# STM32G081xx register map
File version: 1.0
Registers are 32-bit, read-write, reset 0x0 unless marked. A register's access mark holds for its fields unless they carry their own. Offsets are from the block's base; [hi:lo] are bit positions; {n}, {i} and the like mark numbered series.

## PWR — Power Control
Base 0x40007000
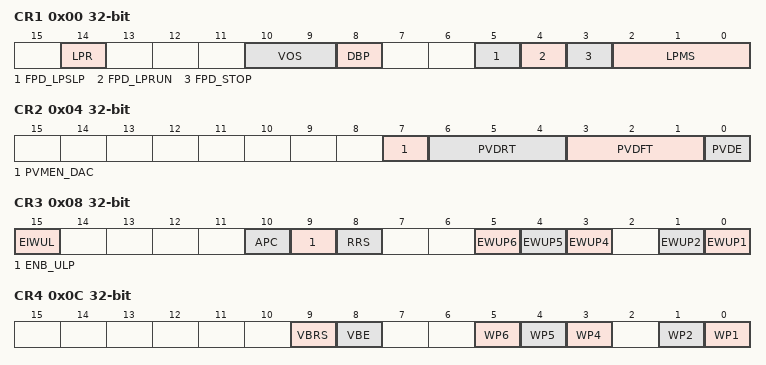
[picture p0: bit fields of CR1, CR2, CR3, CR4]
0x00 CR1 — PWR Power Control Register 1
  [14] LPR — Regulator Low-Power Run mode
  [10:9] VOS — Voltage scaling
    1=SCALE1; 2=SCALE2
  [8] DBP — Disable Backup Domain write protection
  [5] FPD_LPSLP — Flash power down mode during sleep
  [4] FPD_LPRUN — Flash power down mode during run
  [3] FPD_STOP — Flash power down mode during stop
  [2:0] LPMS — Low Power Mode Selection
    0=STOP0; 1=STOP1; 3=STANDBY; 4=SHUTDOWN
0x04 CR2 — PWR Power Control Register 2
  [7] PVMEN_DAC — DAC supply voltage monitoring enable
  [6:4] PVDRT — PVD Rising Threshold Selection bit field
    {v}=PVDHLEVEL_{v} (v=0..7)
  [3:1] PVDFT — PVD Falling Threshold Selection bit field
    {v}=PVDLLEVEL_{v} (v=0..6)
  [0] PVDE — Programmable Voltage Detector Enable
0x08 CR3 — PWR Power Control Register 3
  [15] EIWUL — Enable Internal Wake-up line
  [10] APC — Apply pull-up and pull-down configuration
  [9] ENB_ULP — Enable sampling resistor bridge in the LPMU_RESET block
  [8] RRS — RAM retention in Standby mode
  [5] EWUP6 — Enable WKUP pin 6
  [4] EWUP5 — Enable WKUP pin 5
  [3] EWUP4 — Enable WKUP pin 4
  [1] EWUP2 — Enable WKUP pin 2
  [0] EWUP1 — Enable WKUP pin 1
0x0C CR4 — PWR Power Control Register 4
  [9] VBRS — VBAT Battery charging Resistor Selection
    0=RESISTOR_5K; 1=RESISTOR_1_5K
  [8] VBE — VBAT Battery charging Enable
  [5] WP6 — Wake-Up Pin 6 polarity
  [4] WP5 — Wake-Up Pin 5 polarity
  [3] WP4 — Wake-Up Pin 4 polarity
  [1] WP2 — Wake-Up Pin 2 polarity
  [0] WP1 — Wake-Up Pin 1 polarity
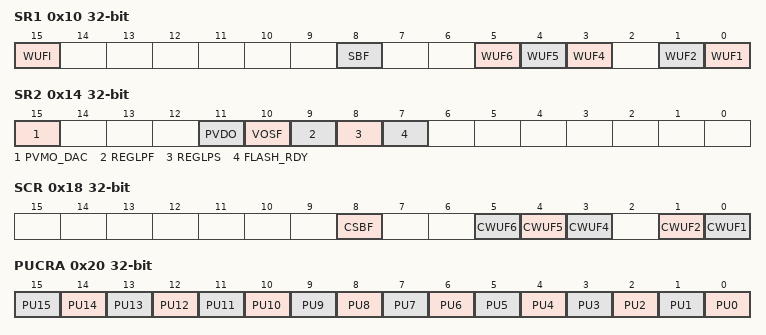
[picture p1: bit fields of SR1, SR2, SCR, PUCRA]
0x10 SR1 — PWR Power Status Register 1
  [15] WUFI — Wakeup Flag Internal
  [8] SBF — Standby Flag
  [5] WUF6 — Wakeup Flag 6
  [4] WUF5 — Wakeup Flag 5
  [3] WUF4 — Wakeup Flag 4
  [1] WUF2 — Wakeup Flag 2
  [0] WUF1 — Wakeup Flag 1
0x14 SR2 — PWR Power Status Register 2
  [15] PVMO_DAC — VDDA monitoring output flag
  [11] PVDO — Power voltage detector output
  [10] VOSF — Voltage Scaling Flag
  [9] REGLPF — Regulator Low Power flag
  [8] REGLPS — Regulator Low Power started
  [7] FLASH_RDY — Flash Ready
0x18 SCR — PWR Power Status Clear Register
  [8] CSBF — Clear Standby Flag
  [5] CWUF6 — Clear Wake-up Flag 6
  [4] CWUF5 — Clear Wake-up Flag 5
  [3] CWUF4 — Clear Wake-up Flag 4
  [1] CWUF2 — Clear Wake-up Flag 2
  [0] CWUF1 — Clear Wake-up Flag 1
0x20 PUCRA — PWR Pull-Up Control Register of port A
  [n] PU{n} (n=0..15) — Pin PA{n} Pull-Up set
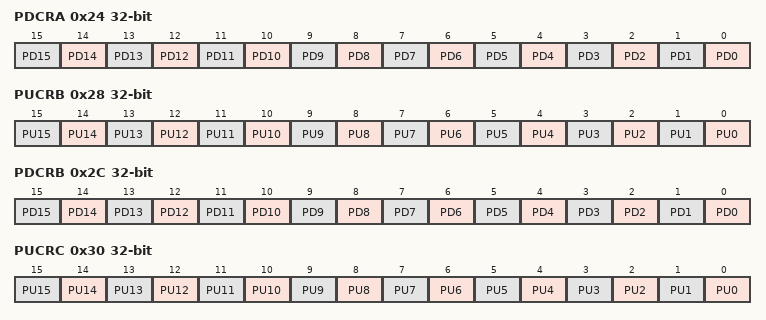
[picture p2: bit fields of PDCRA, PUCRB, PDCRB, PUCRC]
0x24 PDCRA — PWR Pull-Down Control Register of port A
  [n] PD{n} (n=0..15) — Pin PA{n} Pull-Down set
0x28 PUCRB — PWR Pull-Up Control Register of port B
  [n] PU{n} (n=0..15) — Pin PB{n} Pull-Up set
0x2C PDCRB — PWR Pull-Down Control Register of port B
  [n] PD{n} (n=0..15) — Pin PB{n} Pull-Down set
0x30 PUCRC — PWR Pull-Up Control Register of port C
  [n] PU{n} (n=0..15) — Pin PC{n} Pull-Up set
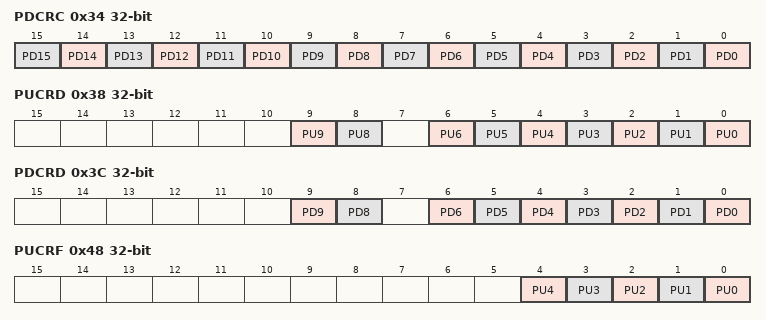
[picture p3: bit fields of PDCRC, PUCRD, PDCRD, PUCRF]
0x34 PDCRC — PWR Pull-Down Control Register of port C
  [n] PD{n} (n=0..15) — Pin PC{n} Pull-Down set
0x38 PUCRD — PWR Pull-Up Control Register of port D
  [9] PU9 — Pin PD9 Pull-Up set
  [8] PU8 — Pin PD8 Pull-Up set
  [n] PU{n} (n=0..6) — Pin PD{n} Pull-Up set
0x3C PDCRD — PWR Pull-Down Control Register of port D
  [9] PD9 — Pin PD9 Pull-Down set
  [8] PD8 — Pin PD8 Pull-Down set
  [n] PD{n} (n=0..6) — Pin PD{n} Pull-Down set
0x48 PUCRF — PWR Pull-Up Control Register of port F
  [n] PU{n} (n=0..4) — Pin PF{n} Pull-Up set
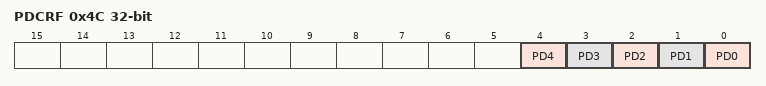
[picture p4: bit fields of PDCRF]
0x4C PDCRF — PWR Pull-Down Control Register of port F
  [n] PD{n} (n=0..4) — Pin PF{n} Pull-Down set

## CEC — HDMI-CEC
Base 0x40007800
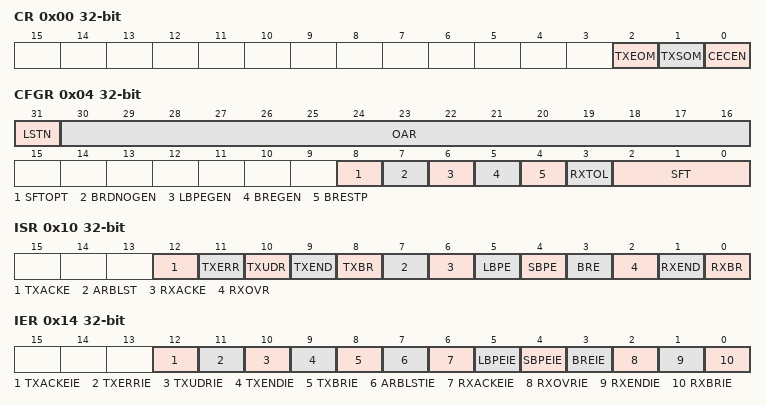
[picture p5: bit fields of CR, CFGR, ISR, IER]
0x00 CR — CEC control register
  [2] TXEOM — CEC Tx End Of Message
  [1] TXSOM — CEC Tx Start Of Message
  [0] CECEN — CEC Enable
0x04 CFGR — CEC configuration register
  [31] LSTN — CEC Listen mode
  [30:16] OAR — CEC Own Address
  [8] SFTOPT — CEC Signal Free Time optional
  [7] BRDNOGEN — CEC Broadcast No Error generation
  [6] LBPEGEN — CEC Long Bit Period Error gener
  [5] BREGEN — CEC Bit Rising Error generation
  [4] BRESTP — CEC Rx Stop
  [3] RXTOL — CEC Tolerance
  [2:0] SFT — CEC Signal Free Time
0x08 TXDR — CEC Tx data register
  [7:0] TXD — CEC Tx Data
0x0C RXDR — CEC Rx Data Register
  [7:0] RXD — CEC Rx Data
0x10 ISR — CEC Interrupt and Status Register
  [12] TXACKE — CEC Tx Missing Acknowledge
  [11] TXERR — CEC Tx-Error
  [10] TXUDR — CEC Tx-Buffer Underrun
  [9] TXEND — CEC End of Transmission
  [8] TXBR — CEC Tx Byte Request
  [7] ARBLST — CEC Arbitration Lost
  [6] RXACKE — CEC Rx Missing Acknowledge
  [5] LBPE — CEC Rx Long Bit period Error
  [4] SBPE — CEC Rx Short Bit period Error
  [3] BRE — CEC Rx Bit Rising Error
  [2] RXOVR — CEC Rx-Overrun
  [1] RXEND — CEC End Of Reception
  [0] RXBR — CEC Rx-Byte Received
0x14 IER — CEC interrupt enable register
  [12] TXACKEIE — CEC Tx Missing Acknowledge IT Enable
  [11] TXERRIE — CEC Tx-Error IT Enable
  [10] TXUDRIE — CEC Tx-Buffer Underrun IT Enable
  [9] TXENDIE — CEC End of Transmission IT Enable
  [8] TXBRIE — CEC Tx Byte Request IT Enable
  [7] ARBLSTIE — CEC Arbitration Lost IT Enable
  [6] RXACKEIE — CEC Rx Missing Acknowledge IT Enable
  [5] LBPEIE — CEC Rx Long Bit period Error IT Enable
  [4] SBPEIE — CEC Rx Short Bit period Error IT Enable
  [3] BREIE — CEC Rx Bit Rising Error IT Enable
  [2] RXOVRIE — CEC Rx-Overrun IT Enable
  [1] RXENDIE — CEC End Of Reception IT Enable
  [0] RXBRIE — CEC Rx-Byte Received IT Enable
